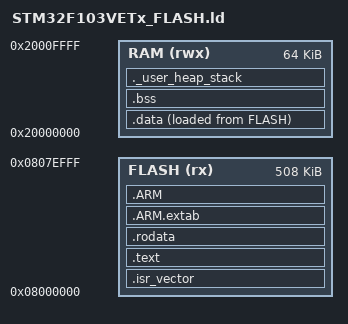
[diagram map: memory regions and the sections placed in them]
/**
 * Linker script for STM32F103VET6
 * Flash: 512KB (0x08000000 - 0x0807FFFF)
 * RAM:   64KB  (0x20000000 - 0x2000FFFF)
 *
 * Last 4KB (0x0807F000-0x0807FFFF) reserved for parameter storage.
 * Application code limited to 508KB.
 */

ENTRY(Reset_Handler)

_estack = ORIGIN(RAM) + LENGTH(RAM);

_Min_Heap_Size = 0x400;     /* 1KB heap (mostly unused with FreeRTOS) */
_Min_Stack_Size = 0x400;    /* 1KB MSP stack */

MEMORY
{
    FLASH (rx)  : ORIGIN = 0x08000000, LENGTH = 508K   /* 512K - 4K param reserved */
    RAM   (rwx) : ORIGIN = 0x20000000, LENGTH = 64K
}

SECTIONS
{
    .isr_vector :
    {
        . = ALIGN(4);
        KEEP(*(.isr_vector))
        . = ALIGN(4);
    } >FLASH

    .text :
    {
        . = ALIGN(4);
        *(.text)
        *(.text*)
        *(.glue_7)
        *(.glue_7t)
        KEEP(*(.init))
        KEEP(*(.fini))
        . = ALIGN(4);
        _etext = .;
    } >FLASH

    .rodata :
    {
        . = ALIGN(4);
        *(.rodata)
        *(.rodata*)
        . = ALIGN(4);
    } >FLASH

    .ARM.extab :
    {
        *(.ARM.extab* .gnu.linkonce.armextab.*)
    } >FLASH

    .ARM :
    {
        __exidx_start = .;
        *(.ARM.exidx*)
        __exidx_end = .;
    } >FLASH

    _sidata = LOADADDR(.data);

    .data :
    {
        . = ALIGN(4);
        _sdata = .;
        *(.data)
        *(.data*)
        . = ALIGN(4);
        _edata = .;
    } >RAM AT> FLASH

    .bss :
    {
        . = ALIGN(4);
        _sbss = .;
        __bss_start__ = _sbss;
        *(.bss)
        *(.bss*)
        *(COMMON)
        . = ALIGN(4);
        _ebss = .;
        __bss_end__ = _ebss;
    } >RAM

    ._user_heap_stack :
    {
        . = ALIGN(8);
        PROVIDE(end = .);
        PROVIDE(_end = .);
        . = . + _Min_Heap_Size;
        . = . + _Min_Stack_Size;
        . = ALIGN(8);
    } >RAM

    /DISCARD/ :
    {
        libc.a(*)
        libm.a(*)
        libgcc.a(*)
    }
}
